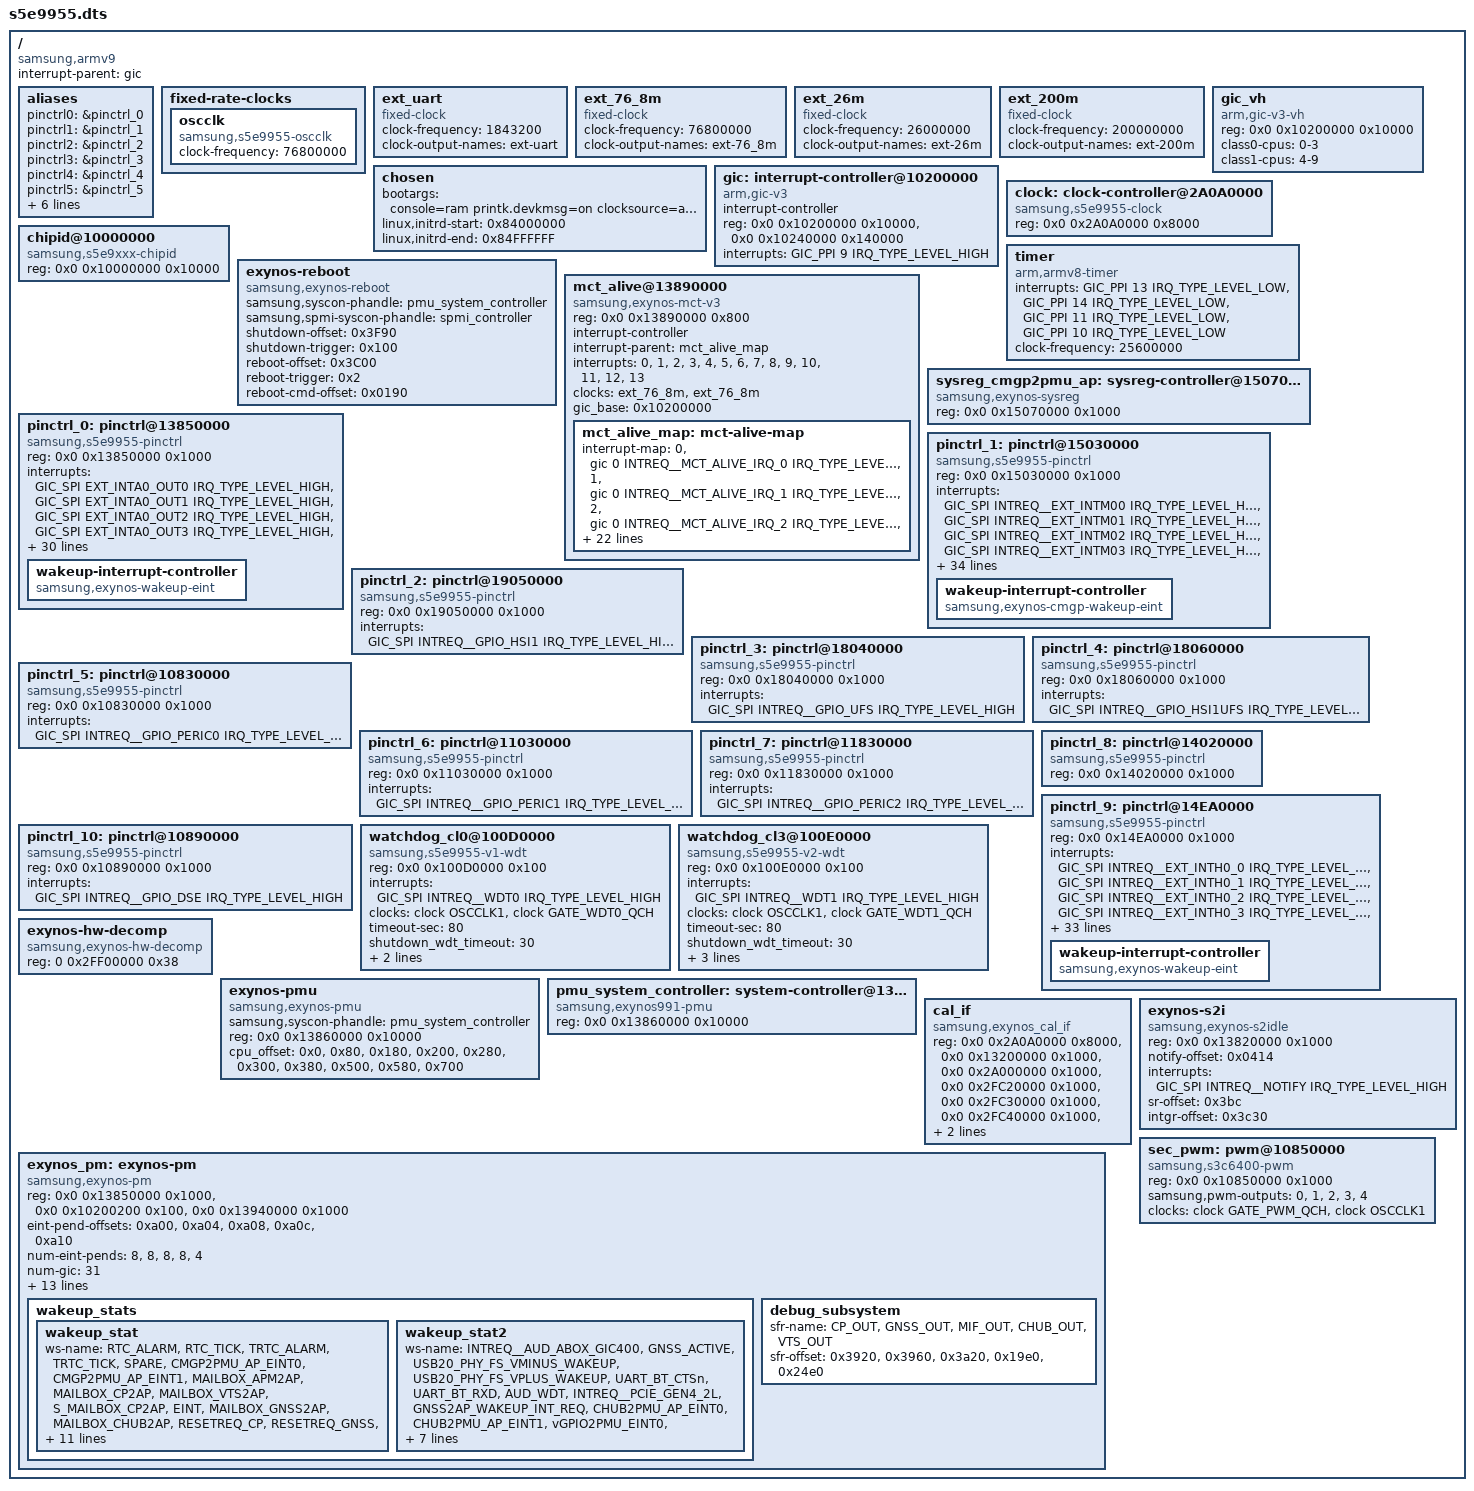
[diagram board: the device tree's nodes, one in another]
/*
 * SAMSUNG S5E9955 SoC device tree source
 *
 * Copyright (c) 2023 Samsung Electronics Co., Ltd.
 *             http://www.samsung.com
 *
 * SAMSUNG S5E9955 SoC device nodes are listed in this file.
 * EXYNOS based board files can include this file and provide
 * values for board specfic bindings.
 *
 * This program is free software; you can redistribute it and/or modify
 * it under the terms of the GNU General Public License version 2 as
 * published by the Free Software Foundation.
 */

/dts-v1/;
/plugin/;
#include <dt-bindings/clock/s5e9955.h>
#include <dt-bindings/interrupt-controller/s5e9955.h>
#include <dt-bindings/soc/samsung/s5e9955-dm.h>
#include <dt-bindings/soc/samsung/s5e9955-devfreq.h>
#include <dt-bindings/soc/samsung/exynos_pm_qos.h>
#include "s5e9955-pinctrl.dtsi"
#include "s5e9955-usi.dtsi"
#include "s5e9955-drm-dpu.dtsi"
#include "s5e9955-cpu.dtsi"
#include "s5e9955-pm-domains.dtsi"
#include "s5e9955-ufs.dtsi"
#include "s5e9955-usb.dtsi"
#include "s5e9955-npu.dtsi"
#include "s5e9955-esca.dtsi"
#include "s5e9955-rmem.dtsi"
#include "s5e9955-security.dtsi"
#include "s5e9955-dma-heap.dtsi"
#include "s5e9955-sysmmu.dtsi"
#include "s5e9955-debug.dtsi"
#include "s5e9955-rmem.dtsi"
#include "s5e9955-power.dtsi"
#include "s5e9955-m2m.dtsi"
#include "s5e9955-mfc.dtsi"
#include "s5e9955-wfd.dtsi"
#include "s5e9955-xperf.dtsi"
#include "s5e9955-ems.dtsi"
#include "s5e9955-audio.dtsi"
#include "s5e9955-camera.dtsi"
#include "s5e9955-pcie.dtsi"
#include "s5e9955-chub.dtsi"
#include "s5e9955-wlbt.dtsi"
#include "s5e9955-sgpu.dtsi"
#include "s5e9955-uarch.dtsi"
#include "s5e9955-profiler.dtsi"
#include "s5e9955-mifgov.dtsi"

/ {
	compatible = "samsung,armv9", "samsung,s5e9955";
	interrupt-parent = <&gic>;
	#address-cells = <2>;
	#size-cells = <1>;

	aliases {
		pinctrl0 = &pinctrl_0;
		pinctrl1 = &pinctrl_1;
		pinctrl2 = &pinctrl_2;
		pinctrl3 = &pinctrl_3;
		pinctrl4 = &pinctrl_4;
		pinctrl5 = &pinctrl_5;
		pinctrl6 = &pinctrl_6;
		pinctrl7 = &pinctrl_7;
		pinctrl8 = &pinctrl_8;
		pinctrl9 = &pinctrl_9;
		pinctrl10 = &pinctrl_10;

		uart0 = &serial_0;
	};

	fixed-rate-clocks {
		oscclk {
			compatible = "samsung,s5e9955-oscclk";
			clock-frequency = <76800000>;
		};
	};

	ext_uart: ext_uart {
		compatible = "fixed-clock";
		#clock-cells = <0>;
		clock-frequency = <1843200>;
		clock-output-names = "ext-uart";
	};

	ext_76_8m: ext_76_8m {
		compatible = "fixed-clock";
		#clock-cells = <0>;
		clock-frequency = <76800000>;
		clock-output-names = "ext-76_8m";
	};

	ext_26m: ext_26m {
		compatible = "fixed-clock";
		#clock-cells = <0>;
		clock-frequency = <26000000>;
		clock-output-names = "ext-26m";
	};

	ext_200m: ext_200m {
		compatible = "fixed-clock";
		#clock-cells = <0>;
		clock-frequency = <200000000>;
		clock-output-names = "ext-200m";
	};

	chosen: chosen {
		bootargs = "console=ram printk.devkmsg=on clocksource=arch_sys_counter clk_ignore_unused firmware_class.path=/vendor/firmware rcupdate.rcu_expedited=1 swiotlb=noforce loop.max_part=7 kvm-arm.protected_modules=exynos-pkvm-module,exynos-pkvm-s2mpu-module cpufreq.default_governor=energy_aware transparent_hugepage=always s3c2410_wdt_ext.tmr_atboot=1 restrict_cma_redirect ttm.pages_limit=4194304 sysctl.kernel.sched_util_clamp_min_rt_default=0 sgpu.lockup_timeout=5000 memblock_memsize=procfs kasan_inval_dcache";
		linux,initrd-start = <0x84000000>;
		linux,initrd-end = <0x84FFFFFF>;
	};

	gic:interrupt-controller@10200000 {
		compatible = "arm,gic-v3";
		#interrupt-cells = <3>;
		interrupt-controller;
		reg = <0x0 0x10200000 0x10000>,         /* GICD */
		      <0x0 0x10240000 0x140000>;        /* GICR * 10 */
		interrupts = <GIC_PPI 9 IRQ_TYPE_LEVEL_HIGH>;
	};

	gic_vh: gic_vh {
		compatible = "arm,gic-v3-vh";
		reg = <0x0 0x10200000 0x10000>;		/* GICD */
		class0-cpus = "0-3";
		class1-cpus = "4-9";
	};

	clock: clock-controller@2A0A0000 {
		compatible = "samsung,s5e9955-clock";
		reg = <0x0 0x2A0A0000 0x8000>;
		#clock-cells = <1>;
	};

	chipid@10000000 {
		compatible = "samsung,s5e9xxx-chipid";
		reg = <0x0 0x10000000 0x10000>;
	};

	timer {
		compatible = "arm,armv8-timer";
		interrupts = <GIC_PPI 13 IRQ_TYPE_LEVEL_LOW>,
			     <GIC_PPI 14 IRQ_TYPE_LEVEL_LOW>,
			     <GIC_PPI 11 IRQ_TYPE_LEVEL_LOW>,
			     <GIC_PPI 10 IRQ_TYPE_LEVEL_LOW>;
		clock-frequency = <25600000>;
	};

	exynos-reboot {
		compatible = "samsung,exynos-reboot";
		samsung,syscon-phandle = <&pmu_system_controller>;
		samsung,spmi-syscon-phandle = <&spmi_controller>;
		shutdown-offset = <0x3F90>;
		shutdown-trigger = <0x100>;
		reboot-offset = <0x3C00>;
		reboot-trigger = <0x2>;
		reboot-cmd-offset = <0x0190>;
		status = "okay";
	};

	mct_alive@13890000 {
		compatible = "samsung,exynos-mct-v3";
		reg = <0x0 0x13890000 0x800>;
		interrupt-controller;
		#interrupt-cells = <1>;
		interrupt-parent = <&mct_alive_map>;
		interrupts =    <0>, <1>, <2>, <3>,
				<4>, <5>, <6>, <7>,
				<8>, <9>, <10>, <11>,
				<12>, <13>;
		clocks = <&ext_76_8m>, <&ext_76_8m>;
		clock-names = "fin_pll", "mct";
		gic_base = <0x10200000>;

		mct_alive_map: mct-alive-map {
			#interrupt-cells = <1>;
			#address-cells = <0>;
			#size-cells = <0>;
			interrupt-map = <0 &gic 0 INTREQ__MCT_ALIVE_IRQ_0 IRQ_TYPE_LEVEL_HIGH>,
				<1 &gic 0 INTREQ__MCT_ALIVE_IRQ_1 IRQ_TYPE_LEVEL_HIGH>,
				<2 &gic 0 INTREQ__MCT_ALIVE_IRQ_2 IRQ_TYPE_LEVEL_HIGH>,
				<3 &gic 0 INTREQ__MCT_ALIVE_IRQ_3 IRQ_TYPE_LEVEL_HIGH>,
				<4 &gic 0 INTREQ__MCT_ALIVE_IRQ_4 IRQ_TYPE_LEVEL_HIGH>,
				<5 &gic 0 INTREQ__MCT_ALIVE_IRQ_5 IRQ_TYPE_LEVEL_HIGH>,
				<6 &gic 0 INTREQ__MCT_ALIVE_IRQ_6 IRQ_TYPE_LEVEL_HIGH>,
				<7 &gic 0 INTREQ__MCT_ALIVE_IRQ_7 IRQ_TYPE_LEVEL_HIGH>,
				<8 &gic 0 INTREQ__MCT_ALIVE_IRQ_8 IRQ_TYPE_LEVEL_HIGH>,
				<9 &gic 0 INTREQ__MCT_ALIVE_IRQ_9 IRQ_TYPE_LEVEL_HIGH>,
				<10 &gic 0 INTREQ__MCT_ALIVE_IRQ_10 IRQ_TYPE_LEVEL_HIGH>,
				<11 &gic 0 INTREQ__MCT_ALIVE_IRQ_11 IRQ_TYPE_LEVEL_HIGH>,
				<12 &gic 0 INTREQ__MCT_ALIVE_IRQ_12 IRQ_TYPE_LEVEL_HIGH>,
				<13 &gic 0 INTREQ__MCT_ALIVE_IRQ_13 IRQ_TYPE_LEVEL_HIGH>;
		};
	};

	sysreg_cmgp2pmu_ap: sysreg-controller@15070000 {
		compatible = "samsung,exynos-sysreg", "syscon";
		reg = <0x0 0x15070000 0x1000>;
	};

	/* ALIVE */
	pinctrl_0: pinctrl@13850000 {
		compatible = "samsung,s5e9955-pinctrl";
		reg = <0x0 0x13850000 0x1000>;
		interrupts = <GIC_SPI EXT_INTA0_OUT0 IRQ_TYPE_LEVEL_HIGH>,
			     <GIC_SPI EXT_INTA0_OUT1 IRQ_TYPE_LEVEL_HIGH>,
			     <GIC_SPI EXT_INTA0_OUT2 IRQ_TYPE_LEVEL_HIGH>,
			     <GIC_SPI EXT_INTA0_OUT3 IRQ_TYPE_LEVEL_HIGH>,
			     <GIC_SPI EXT_INTA0_OUT4 IRQ_TYPE_LEVEL_HIGH>,
			     <GIC_SPI EXT_INTA0_OUT5 IRQ_TYPE_LEVEL_HIGH>,
			     <GIC_SPI EXT_INTA0_OUT6 IRQ_TYPE_LEVEL_HIGH>,
			     <GIC_SPI EXT_INTA0_OUT7 IRQ_TYPE_LEVEL_HIGH>,
			     <GIC_SPI EXT_INTA1_OUT0 IRQ_TYPE_LEVEL_HIGH>,
			     <GIC_SPI EXT_INTA1_OUT1 IRQ_TYPE_LEVEL_HIGH>,
			     <GIC_SPI EXT_INTA1_OUT2 IRQ_TYPE_LEVEL_HIGH>,
			     <GIC_SPI EXT_INTA1_OUT3 IRQ_TYPE_LEVEL_HIGH>,
			     <GIC_SPI EXT_INTA1_OUT4 IRQ_TYPE_LEVEL_HIGH>,
			     <GIC_SPI EXT_INTA1_OUT5 IRQ_TYPE_LEVEL_HIGH>,
			     <GIC_SPI EXT_INTA1_OUT6 IRQ_TYPE_LEVEL_HIGH>,
			     <GIC_SPI EXT_INTA1_OUT7 IRQ_TYPE_LEVEL_HIGH>,
			     <GIC_SPI EXT_INTA2_OUT0 IRQ_TYPE_LEVEL_HIGH>,
			     <GIC_SPI EXT_INTA2_OUT1 IRQ_TYPE_LEVEL_HIGH>,
			     <GIC_SPI EXT_INTA2_OUT2 IRQ_TYPE_LEVEL_HIGH>,
			     <GIC_SPI EXT_INTA2_OUT3 IRQ_TYPE_LEVEL_HIGH>,
			     <GIC_SPI EXT_INTA2_OUT4 IRQ_TYPE_LEVEL_HIGH>,
			     <GIC_SPI EXT_INTA2_OUT5 IRQ_TYPE_LEVEL_HIGH>,
			     <GIC_SPI EXT_INTA2_OUT6 IRQ_TYPE_LEVEL_HIGH>,
			     <GIC_SPI EXT_INTA2_OUT7 IRQ_TYPE_LEVEL_HIGH>,
			     <GIC_SPI EXT_INTA3_OUT0 IRQ_TYPE_LEVEL_HIGH>,
			     <GIC_SPI EXT_INTA3_OUT1 IRQ_TYPE_LEVEL_HIGH>,
			     <GIC_SPI EXT_INTA3_OUT2 IRQ_TYPE_LEVEL_HIGH>,
			     <GIC_SPI EXT_INTA3_OUT3 IRQ_TYPE_LEVEL_HIGH>,
			     <GIC_SPI EXT_INTA3_OUT4 IRQ_TYPE_LEVEL_HIGH>,
			     <GIC_SPI EXT_INTA3_OUT5 IRQ_TYPE_LEVEL_HIGH>,
			     <GIC_SPI EXT_INTA3_OUT6 IRQ_TYPE_LEVEL_HIGH>,
			     <GIC_SPI EXT_INTA3_OUT7 IRQ_TYPE_LEVEL_HIGH>,
			     <GIC_SPI EXT_INTA4_OUT0 IRQ_TYPE_LEVEL_HIGH>,
			     <GIC_SPI EXT_INTA4_OUT1 IRQ_TYPE_LEVEL_HIGH>;

		wakeup-interrupt-controller {
			compatible = "samsung,exynos-wakeup-eint";
		};
	};

	/* CMGP */
	pinctrl_1: pinctrl@15030000{
		compatible = "samsung,s5e9955-pinctrl";
		reg = <0x0 0x15030000 0x1000>;
		interrupts = <GIC_SPI INTREQ__EXT_INTM00 IRQ_TYPE_LEVEL_HIGH>,
			     <GIC_SPI INTREQ__EXT_INTM01 IRQ_TYPE_LEVEL_HIGH>,
			     <GIC_SPI INTREQ__EXT_INTM02 IRQ_TYPE_LEVEL_HIGH>,
			     <GIC_SPI INTREQ__EXT_INTM03 IRQ_TYPE_LEVEL_HIGH>,
			     <GIC_SPI INTREQ__EXT_INTM04 IRQ_TYPE_LEVEL_HIGH>,
			     <GIC_SPI INTREQ__EXT_INTM05 IRQ_TYPE_LEVEL_HIGH>,
			     <GIC_SPI INTREQ__EXT_INTM06 IRQ_TYPE_LEVEL_HIGH>,
			     <GIC_SPI INTREQ__EXT_INTM07 IRQ_TYPE_LEVEL_HIGH>,
			     <GIC_SPI INTREQ__EXT_INTM08 IRQ_TYPE_LEVEL_HIGH>,
			     <GIC_SPI INTREQ__EXT_INTM09 IRQ_TYPE_LEVEL_HIGH>,
			     <GIC_SPI INTREQ__EXT_INTM10 IRQ_TYPE_LEVEL_HIGH>,
			     <GIC_SPI INTREQ__EXT_INTM11 IRQ_TYPE_LEVEL_HIGH>,
			     <GIC_SPI INTREQ__EXT_INTM12 IRQ_TYPE_LEVEL_HIGH>,
			     <GIC_SPI INTREQ__EXT_INTM13 IRQ_TYPE_LEVEL_HIGH>,
			     <GIC_SPI INTREQ__EXT_INTM14 IRQ_TYPE_LEVEL_HIGH>,
			     <GIC_SPI INTREQ__EXT_INTM15 IRQ_TYPE_LEVEL_HIGH>,
			     <GIC_SPI INTREQ__EXT_INTM16 IRQ_TYPE_LEVEL_HIGH>,
			     <GIC_SPI INTREQ__EXT_INTM17 IRQ_TYPE_LEVEL_HIGH>,
			     <GIC_SPI INTREQ__EXT_INTM18 IRQ_TYPE_LEVEL_HIGH>,
			     <GIC_SPI INTREQ__EXT_INTM19 IRQ_TYPE_LEVEL_HIGH>,
			     <GIC_SPI INTREQ__EXT_INTM20 IRQ_TYPE_LEVEL_HIGH>,
			     <GIC_SPI INTREQ__EXT_INTM21 IRQ_TYPE_LEVEL_HIGH>,
			     <GIC_SPI INTREQ__EXT_INTM22 IRQ_TYPE_LEVEL_HIGH>,
			     <GIC_SPI INTREQ__EXT_INTM23 IRQ_TYPE_LEVEL_HIGH>,
			     <GIC_SPI INTREQ__EXT_INTM24 IRQ_TYPE_LEVEL_HIGH>,
			     <GIC_SPI INTREQ__EXT_INTM25 IRQ_TYPE_LEVEL_HIGH>,
			     <GIC_SPI INTREQ__EXT_INTM26 IRQ_TYPE_LEVEL_HIGH>,
			     <GIC_SPI INTREQ__EXT_INTM27 IRQ_TYPE_LEVEL_HIGH>,
			     <GIC_SPI INTREQ__EXT_INTM28 IRQ_TYPE_LEVEL_HIGH>,
			     <GIC_SPI INTREQ__EXT_INTM29 IRQ_TYPE_LEVEL_HIGH>,
			     <GIC_SPI INTREQ__EXT_INTM30 IRQ_TYPE_LEVEL_HIGH>,
			     <GIC_SPI INTREQ__EXT_INTM31 IRQ_TYPE_LEVEL_HIGH>,
			     <GIC_SPI INTREQ__EXT_INTM32 IRQ_TYPE_LEVEL_HIGH>,
			     <GIC_SPI INTREQ__EXT_INTM33 IRQ_TYPE_LEVEL_HIGH>,
			     <GIC_SPI INTREQ__EXT_INTM34 IRQ_TYPE_LEVEL_HIGH>,
			     <GIC_SPI INTREQ__EXT_INTM35 IRQ_TYPE_LEVEL_HIGH>,
			     <GIC_SPI INTREQ__EXT_INTM36 IRQ_TYPE_LEVEL_HIGH>;

		samsung,syscon-phandle = <&sysreg_cmgp2pmu_ap>;
		wakeup-interrupt-controller {
			compatible = "samsung,exynos-cmgp-wakeup-eint";
		};
	};

	/* HSI1 */
	pinctrl_2: pinctrl@19050000 {
		compatible = "samsung,s5e9955-pinctrl";
		reg = <0x0 0x19050000 0x1000>;
		interrupts = <GIC_SPI INTREQ__GPIO_HSI1 IRQ_TYPE_LEVEL_HIGH>;
	};

	/* UFS */
	pinctrl_3: pinctrl@18040000 {
		compatible = "samsung,s5e9955-pinctrl";
		reg = <0x0 0x18040000 0x1000>;
		interrupts = <GIC_SPI INTREQ__GPIO_UFS IRQ_TYPE_LEVEL_HIGH>;
	};

	/* HSI1UFS */
	pinctrl_4: pinctrl@18060000 {
		compatible = "samsung,s5e9955-pinctrl";
		reg = <0x0 0x18060000 0x1000>;
		interrupts = <GIC_SPI INTREQ__GPIO_HSI1UFS IRQ_TYPE_LEVEL_HIGH>;
	};

	/* PERIC0 */
	pinctrl_5: pinctrl@10830000 {
		compatible = "samsung,s5e9955-pinctrl";
		reg = <0x0 0x10830000 0x1000>;
		interrupts = <GIC_SPI INTREQ__GPIO_PERIC0 IRQ_TYPE_LEVEL_HIGH>;
	};

	/* PERIC1 */
	pinctrl_6: pinctrl@11030000 {
		compatible = "samsung,s5e9955-pinctrl";
		reg = <0x0 0x11030000 0x1000>;
		interrupts = <GIC_SPI INTREQ__GPIO_PERIC1 IRQ_TYPE_LEVEL_HIGH>;
	};

	/* PERIC2 */
	pinctrl_7: pinctrl@11830000 {
		compatible = "samsung,s5e9955-pinctrl";
		reg = <0x0 0x11830000 0x1000>;
		interrupts = <GIC_SPI INTREQ__GPIO_PERIC2 IRQ_TYPE_LEVEL_HIGH>;
	};

	/* VTS */
	pinctrl_8: pinctrl@14020000 {
		compatible = "samsung,s5e9955-pinctrl";
		reg = <0x0 0x14020000 0x1000>;
		/* NO Pinctrl VTS GPIO interrupts */
	};

	/* CHUBVTS */
	pinctrl_9: pinctrl@14EA0000 {
		compatible = "samsung,s5e9955-pinctrl";
		reg = <0x0 0x14EA0000 0x1000>;
		interrupts = <GIC_SPI INTREQ__EXT_INTH0_0 IRQ_TYPE_LEVEL_HIGH>,
			     <GIC_SPI INTREQ__EXT_INTH0_1 IRQ_TYPE_LEVEL_HIGH>,
			     <GIC_SPI INTREQ__EXT_INTH0_2 IRQ_TYPE_LEVEL_HIGH>,
			     <GIC_SPI INTREQ__EXT_INTH0_3 IRQ_TYPE_LEVEL_HIGH>,
			     <GIC_SPI INTREQ__EXT_INTH1_0 IRQ_TYPE_LEVEL_HIGH>,
			     <GIC_SPI INTREQ__EXT_INTH1_1 IRQ_TYPE_LEVEL_HIGH>,
			     <GIC_SPI INTREQ__EXT_INTH1_2 IRQ_TYPE_LEVEL_HIGH>,
			     <GIC_SPI INTREQ__EXT_INTH1_3 IRQ_TYPE_LEVEL_HIGH>,
			     <GIC_SPI INTREQ__EXT_INTH2_0 IRQ_TYPE_LEVEL_HIGH>,
			     <GIC_SPI INTREQ__EXT_INTH2_1 IRQ_TYPE_LEVEL_HIGH>,
			     <GIC_SPI INTREQ__EXT_INTH2_2 IRQ_TYPE_LEVEL_HIGH>,
			     <GIC_SPI INTREQ__EXT_INTH2_3 IRQ_TYPE_LEVEL_HIGH>,
			     <GIC_SPI INTREQ__EXT_INTH3_0 IRQ_TYPE_LEVEL_HIGH>,
			     <GIC_SPI INTREQ__EXT_INTH3_1 IRQ_TYPE_LEVEL_HIGH>,
			     <GIC_SPI INTREQ__EXT_INTH3_2 IRQ_TYPE_LEVEL_HIGH>,
			     <GIC_SPI INTREQ__EXT_INTH3_3 IRQ_TYPE_LEVEL_HIGH>,
			     <GIC_SPI INTREQ__EXT_INTH4_0 IRQ_TYPE_LEVEL_HIGH>,
			     <GIC_SPI INTREQ__EXT_INTH4_1 IRQ_TYPE_LEVEL_HIGH>,
			     <GIC_SPI INTREQ__EXT_INTH4_2 IRQ_TYPE_LEVEL_HIGH>,
			     <GIC_SPI INTREQ__EXT_INTH4_3 IRQ_TYPE_LEVEL_HIGH>,
			     <GIC_SPI INTREQ__EXT_INTH5_0 IRQ_TYPE_LEVEL_HIGH>,
			     <GIC_SPI INTREQ__EXT_INTH5_1 IRQ_TYPE_LEVEL_HIGH>,
			     <GIC_SPI INTREQ__EXT_INTH5_2 IRQ_TYPE_LEVEL_HIGH>,
			     <GIC_SPI INTREQ__EXT_INTH5_3 IRQ_TYPE_LEVEL_HIGH>,
			     <GIC_SPI INTREQ__EXT_INTH5_4 IRQ_TYPE_LEVEL_HIGH>,
			     <GIC_SPI INTREQ__EXT_INTH5_5 IRQ_TYPE_LEVEL_HIGH>,
			     <GIC_SPI INTREQ__EXT_INTH5_6 IRQ_TYPE_LEVEL_HIGH>,
			     <GIC_SPI INTREQ__EXT_INTH6_0 IRQ_TYPE_LEVEL_HIGH>,
			     <GIC_SPI INTREQ__EXT_INTH6_1 IRQ_TYPE_LEVEL_HIGH>,
			     <GIC_SPI INTREQ__EXT_INTH7_0 IRQ_TYPE_LEVEL_HIGH>,
			     <GIC_SPI INTREQ__EXT_INTH7_1 IRQ_TYPE_LEVEL_HIGH>,
			     <GIC_SPI INTREQ__EXT_INTH8_0 IRQ_TYPE_LEVEL_HIGH>,
			     <GIC_SPI INTREQ__EXT_INTH8_1 IRQ_TYPE_LEVEL_HIGH>,
			     <GIC_SPI INTREQ__EXT_INTB4_0 IRQ_TYPE_LEVEL_HIGH>,
			     <GIC_SPI INTREQ__EXT_INTB4_1 IRQ_TYPE_LEVEL_HIGH>,
			     <GIC_SPI INTREQ__EXT_INTB4_2 IRQ_TYPE_LEVEL_HIGH>,
			     <GIC_SPI INTREQ__EXT_INTB4_3 IRQ_TYPE_LEVEL_HIGH>;

		wakeup-interrupt-controller {
			compatible = "samsung,exynos-wakeup-eint";
		};
	};

	/* DSE */
	pinctrl_10: pinctrl@10890000 {
		compatible = "samsung,s5e9955-pinctrl";
		reg = <0x0 0x10890000 0x1000>;
		interrupts = <GIC_SPI INTREQ__GPIO_DSE IRQ_TYPE_LEVEL_HIGH>;
	};

	watchdog_cl0@100D0000 {
		compatible = "samsung,s5e9955-v1-wdt";
		reg = <0x0 0x100D0000 0x100>;
		interrupts = <GIC_SPI INTREQ__WDT0 IRQ_TYPE_LEVEL_HIGH>;
		clocks = <&clock OSCCLK1>, <&clock GATE_WDT0_QCH>;
		clock-names = "rate_watchdog", "gate_watchdog";
		timeout-sec = <80>;
		shutdown_wdt_timeout = <30>;
		samsung,syscon-phandle = <&pmu_system_controller>;
		index = <0>; /* if little cluster then index is 0 */
		status = "okay";
	};

	watchdog_cl3@100E0000 {
		compatible = "samsung,s5e9955-v2-wdt";
		reg = <0x0 0x100E0000 0x100>;
		interrupts = <GIC_SPI INTREQ__WDT1 IRQ_TYPE_LEVEL_HIGH>;
		clocks = <&clock OSCCLK1>, <&clock GATE_WDT1_QCH>;
		clock-names = "rate_watchdog", "gate_watchdog";
		timeout-sec = <80>;
		shutdown_wdt_timeout = <30>;
		samsung,syscon-phandle = <&pmu_system_controller>;
		index = <1>; /* if big cluster then index is 1 */
		use_multistage_wdt;
		status = "okay";
	};

	exynos-hw-decomp {
		compatible = "samsung,exynos-hw-decomp";
		reg = <0 0x2FF00000 0x38>;
	};

	exynos-pmu {
		compatible = "samsung,exynos-pmu";
		samsung,syscon-phandle = <&pmu_system_controller>;
		reg = <0x0 0x13860000 0x10000>;
		reg-names = "pmu_alive";
		cpu_offset = <0x0>, <0x80>, <0x180>, <0x200>,
			   <0x280>, <0x300>, <0x380>, <0x500>,
			   <0x580>, <0x700>;
	};

	pmu_system_controller: system-controller@13860000 {
		compatible = "samsung,exynos991-pmu", "syscon";
		reg = <0x0 0x13860000 0x10000>;
	};

	cal_if {
		compatible = "samsung,exynos_cal_if";
		reg = <0x0 0x2A0A0000 0x8000>, /* CMU_TOP */
			<0x0 0x13200000 0x1000>, /* CMU_AUD */
			<0x0 0x2A000000 0x1000>, /* CMU_NOCL0 */
			<0x0 0x2FC20000 0x1000>, /* CMU_CPUCL0 */
			<0x0 0x2FC30000 0x1000>, /* CMU_CPUCL1 */
			<0x0 0x2FC40000 0x1000>, /* CMU_CPUCL2*/
			<0x0 0x2FC10000 0x1000>, /* CMU_DSU */
			<0x0 0x10050000 0x1000>; /* CMU_PERIS */
		esca-ipc-channel = <ESCA_IPC_PHY__FVP_CAL>;
	};

	exynos-s2i {
		compatible = "samsung,exynos-s2idle";
	        reg = <0x0 0x13820000 0x1000>;
		reg-names = "sysreg_alive";
		notify-offset = <0x0414>; 	/* SYSREG_ALIVE NOTIFY offset */
		interrupts = <GIC_SPI INTREQ__NOTIFY IRQ_TYPE_LEVEL_HIGH>;	/* SYSREG_ALIVE NOTIFY */
		sr-offset = <0x3bc>;		/* PMU_SPARE7 */
		intgr-offset = <0x3c30>;	/* PMU_SPARE_CTRL */
	};

	exynos_pm: exynos-pm {
		compatible = "samsung,exynos-pm";
	        reg = <0x0 0x13850000 0x1000>,
			<0x0 0x10200200 0x100>,
			<0x0 0x13940000 0x1000>;
		reg-names = "gpio_alive_base",
			"gicd_ispendrn_base",
			"sysreg_vgpio2pmu";

		eint-pend-offsets = <0xa00>, <0xa04>, <0xa08>, <0xa0c>, <0xa10>;
		num-eint-pends = <8>, <8>, <8>, <8>, <4>;
		num-gic = <31>;
		suspend_mode_idx = <8>;         /* SYS_SLEEP */

		/* WAKEUP_STAT,      WAKEUP2_STAT*/
		wakeup_stat_offset = <0x3b50>,         <0x3b54>;
		wakeup_int_en_offset = <0x3b44>,         <0x3b64>;
		wakeup_int_en = <0x0001ff6f>,         <0x14780D>;
		usbl2_wakeup_int_en = <0x0>, <0xC>;
		eint_wakeup_mask_offset = <0x3e40>,      <0x3e44>;
		wakeup-stat-eint = <11>;
		wakeup-stat-rtc = <0>;

		vgpio_wakeup_inten = <0x40fc0>; // check needed
		vgpio_wakeup_inten_offset = <0x288>;

		wake_lock = <0>;                /* 1: held wake_lock */

		pcieon_suspend_available = <1>;
		pcieon_suspend_mode_idx = <13>;  /* SYS_SLEEP_HSI1ON */

		wakeup_stats {
			wakeup_stat {
				ws-name =
					"RTC_ALARM",			/* [0] */
					"RTC_TICK",			/* [1] */
					"TRTC_ALARM",			/* [2] */
					"TRTC_TICK",			/* [3] */
					"SPARE",			/* [4] */
					"CMGP2PMU_AP_EINT0",		/* [5] */
					"CMGP2PMU_AP_EINT1",		/* [6] */
					"MAILBOX_APM2AP",		/* [7] */
					"MAILBOX_CP2AP",		/* [8] */
					"MAILBOX_VTS2AP",		/* [9] */
					"S_MAILBOX_CP2AP",		/* [10] */
					"EINT",				/* [11] */
					"MAILBOX_GNSS2AP",		/* [12] */
					"MAILBOX_CHUB2AP",		/* [13] */
					"RESETREQ_CP",			/* [14] */
					"RESETREQ_GNSS",		/* [15] */
					"USB_REWA",			/* [16] */
					"UFD2AP",			/* [17] */
					"TIMER",			/* [18] */
					"PCIE_GEN4_2L",			/* [19] */
					"CLUSTER0_CPU0_nIRQOUT",	/* [20] */
					"CLUSTER0_CPU1_nIRQOUT",	/* [21] */
					"CLUSTER1_CPU0_nIRQOUT",	/* [22] */
					"CLUSTER1_CPU1_nIRQOUT",	/* [23] */
					"CLUSTER1_CPU2_nIRQOUT",	/* [24] */
					"CLUSTER1_CPU3_nIRQOUT",	/* [25] */
					"CLUSTER1_CPU4_nIRQOUT",	/* [26] */
					"CLUSTER2_CPU0_nIRQOUT",	/* [27] */
					"CLUSTER2_CPU1_nIRQOUT",	/* [28] */
					"CLUSTER3_CPU0_nIRQOUT",	/* [29] */
					"RESERVED",			/* [30] */
					"RESERVED";			/* [31] */
			};
			wakeup_stat2 {
				ws-name =
					"INTREQ__AUD_ABOX_GIC400",	/* [0] */
					"GNSS_ACTIVE",			/* [1] */
					"USB20_PHY_FS_VMINUS_WAKEUP",	/* [2] */
					"USB20_PHY_FS_VPLUS_WAKEUP",	/* [3] */
					"UART_BT_CTSn",			/* [4] */
					"UART_BT_RXD",			/* [5] */
					"AUD_WDT",			/* [6] */
					"INTREQ__PCIE_GEN4_2L",		/* [7] */
					"GNSS2AP_WAKEUP_INT_REQ",	/* [8] */
					"CHUB2PMU_AP_EINT0",		/* [9] */
					"CHUB2PMU_AP_EINT1",		/* [10] */
					"vGPIO2PMU_EINT0",		/* [11] */
					"vGPIO2PMU_EINT1",		/* [12] */
					"VTS_WDT",			/* [13] */
					"CHUB_WDT",			/* [14] */
					"RESERVED",			/* [15] */
					"RESERVED",			/* [16] */
					"MAILBOX_ASM2AP",		/* [17] */
					"INTREQ__USB32DRD_0",		/* [18] */
					"UNPU_WDT",			/* [19] */
					"PSP2AP_WAKEUP",		/* [20] */
					"INTREQ__USB32DRD_1",		/* [21] */
					"INTREQ__FROM_UNPU_TO_HOST",	/* [22] */
					"MAILBOX_APM12AP",		/* [23] */
					"RESERVED",			/* [24] */
					"RESERVED",			/* [25] */
					"RESERVED",			/* [26] */
					"RESERVED",			/* [27] */
					"RESERVED",			/* [28] */
					"RESERVED",			/* [29] */
					"RESERVED",			/* [30] */
					"RESERVED";			/* [31] */
			};
		};
		debug_subsystem {
			sfr-name =
				"CP_OUT",
				"GNSS_OUT",
				"MIF_OUT",
				"CHUB_OUT",
				"VTS_OUT";
			sfr-offset =
				<0x3920>,
				<0x3960>,
				<0x3a20>,
				<0x19e0>,
				<0x24e0>;
		};
	};

	sec_pwm: pwm@10850000 {
		compatible = "samsung,s3c6400-pwm";
		reg = <0x0 0x10850000 0x1000>;
		samsung,pwm-outputs = <0>, <1>, <2>, <3>, <4>;
		#pwm-cells = <3>;
		clocks = <&clock GATE_PWM_QCH>, <&clock OSCCLK1>;
		clock-names = "pwm_pclk", "pwm_sclk";
		status = "okay";
	};
};
